# HDSC_HC32L110 register map
Vendor: HDSC Co.Ltd; Series: ARMCM0P; File version: 1.2
CPU: CM0 r0p0, little endian, no MPU, no FPU, 3 interrupt priority bits
Registers are 32-bit, read-write, reset 0x0 unless marked. A register's access mark holds for its fields unless they carry their own. Offsets are from the block's base; [hi:lo] are bit positions.

## BGR
Base 0x40002400; alternate view of ADC
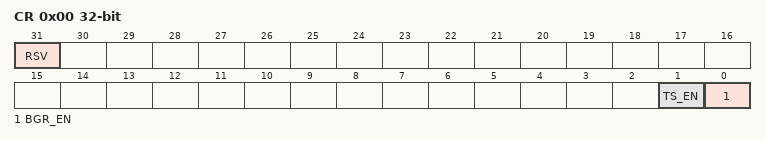
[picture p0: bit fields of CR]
0x00 CR (reset mask 0x3)
  [31] RSV, [1] TS_EN, [0] BGR_EN

## BT0 — desc BT
Base 0x40000C00
Same registers: BT1 0x40000C20, BT2 0x40000C40
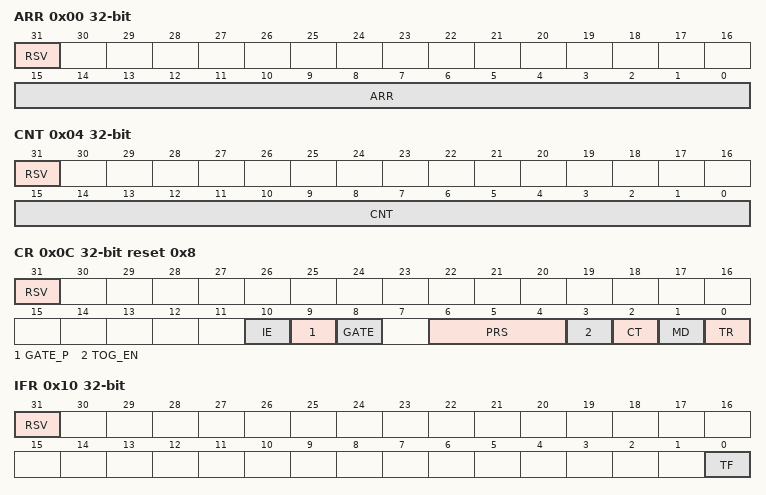
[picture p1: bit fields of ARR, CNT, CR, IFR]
0x00 ARR (reset mask 0xFF)
  [31] RSV, [15:0] ARR
0x04 CNT (reset mask 0xFF)
  [31] RSV, [15:0] CNT
0x08 CNT32
0x0C CR reset 0x8 (reset mask 0x77F)
  [31] RSV, [10] IE, [9] GATE_P, [8] GATE, [6:4] PRS, [3] TOG_EN, [2] CT, [1] MD, [0] TR
0x10 IFR ro (reset mask 0x1)
  [31] RSV rw, [0] TF
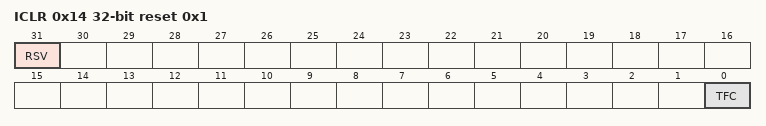
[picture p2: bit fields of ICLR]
0x14 ICLR wo reset 0x1 (reset mask 0x1)
  [31] RSV rw, [0] TFC

## CLK_TRIM
Base 0x40001800
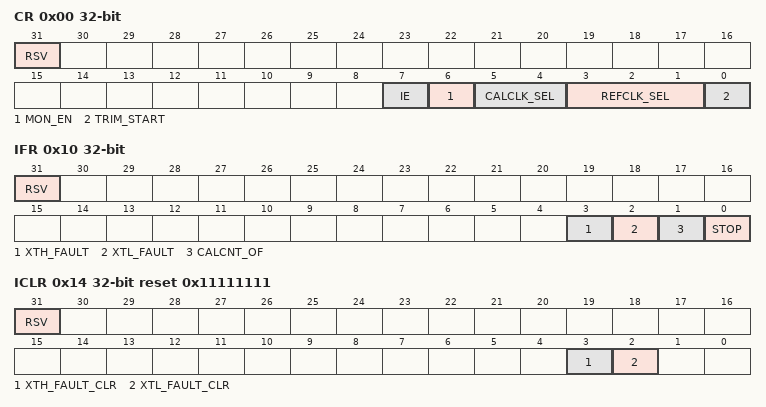
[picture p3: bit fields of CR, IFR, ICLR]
0x00 CR (reset mask 0xFF)
  [31] RSV, [7] IE, [6] MON_EN, [5:4] CALCLK_SEL, [3:1] REFCLK_SEL, [0] TRIM_START
0x04 REFCON
  [31:0] RCNTVAL
0x08 REFCNT ro
0x0C CALCNT ro
0x10 IFR ro (reset mask 0xF)
  [31] RSV rw, [3] XTH_FAULT, [2] XTL_FAULT, [1] CALCNT_OF, [0] STOP
0x14 ICLR reset 0x11111111 (reset mask 0xC)
  [31] RSV, [3] XTH_FAULT_CLR, [2] XTL_FAULT_CLR
0x18 CALCON reset 0xFFFFFFFF
  [31:0] CCNTVAL

## CLOCK
Base 0x40002000
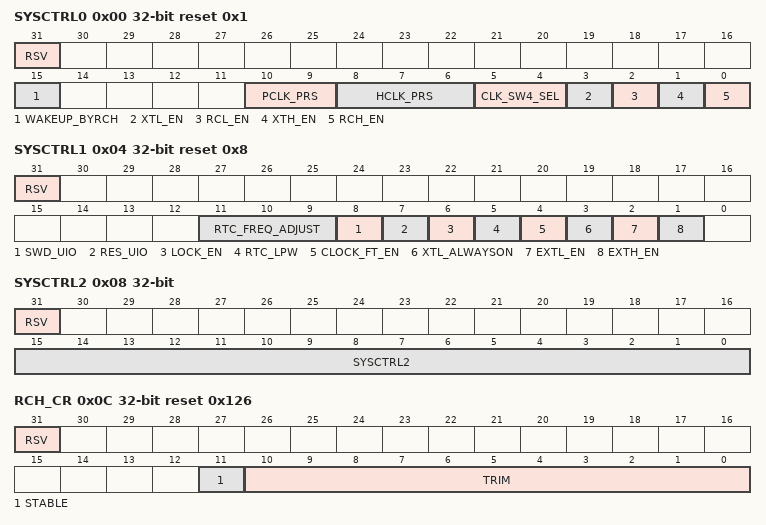
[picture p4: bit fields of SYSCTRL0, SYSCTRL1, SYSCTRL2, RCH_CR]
0x00 SYSCTRL0 reset 0x1 (reset mask 0x87FF)
  [31] RSV, [15] WAKEUP_BYRCH, [10:9] PCLK_PRS, [8:6] HCLK_PRS, [5:4] CLK_SW4_SEL, [3] XTL_EN, [2] RCL_EN, [1] XTH_EN, [0] RCH_EN
0x04 SYSCTRL1 reset 0x8 (reset mask 0xFFE)
  [31] RSV, [11:9] RTC_FREQ_ADJUST, [8] SWD_UIO, [7] RES_UIO, [6] LOCK_EN, [5] RTC_LPW, [4] CLOCK_FT_EN, [3] XTL_ALWAYSON, [2] EXTL_EN, [1] EXTH_EN
0x08 SYSCTRL2 (reset mask 0xFFFF)
  [31] RSV, [15:0] SYSCTRL2
0x0C RCH_CR reset 0x126 (reset mask 0xFFF)
  [31] RSV, [11] STABLE ro, [10:0] TRIM
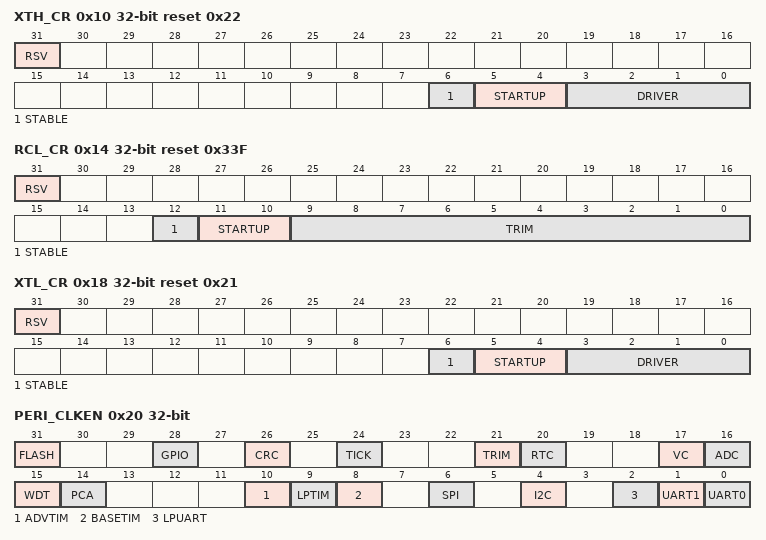
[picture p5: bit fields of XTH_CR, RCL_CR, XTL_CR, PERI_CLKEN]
0x10 XTH_CR reset 0x22 (reset mask 0x7F)
  [31] RSV, [6] STABLE ro, [5:4] STARTUP, [3:0] DRIVER
0x14 RCL_CR reset 0x33F (reset mask 0x1FFF)
  [31] RSV, [12] STABLE ro, [11:10] STARTUP, [9:0] TRIM
0x18 XTL_CR reset 0x21 (reset mask 0x7F)
  [31] RSV, [6] STABLE ro, [5:4] STARTUP, [3:0] DRIVER
0x20 PERI_CLKEN
  [31] FLASH, [28] GPIO, [26] CRC, [24] TICK, [21] TRIM, [20] RTC, [17] VC, [16] ADC, [15] WDT, [14] PCA, [10] ADVTIM, [9] LPTIM, [8] BASETIM, [6] SPI, [4] I2C, [2] LPUART, [1] UART1, [0] UART0
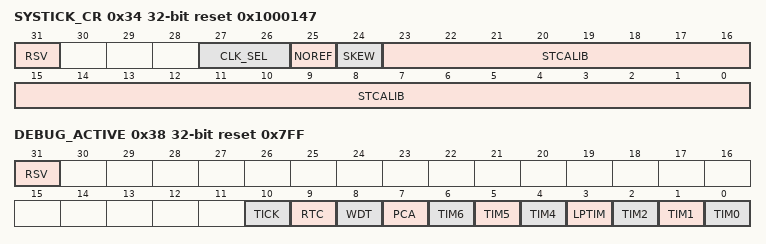
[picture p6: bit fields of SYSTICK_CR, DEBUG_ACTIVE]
0x34 SYSTICK_CR reset 0x1000147 (reset mask 0xFFFFFFF)
  [31] RSV, [27:26] CLK_SEL, [25] NOREF, [24] SKEW, [23:0] STCALIB
0x38 DEBUG_ACTIVE reset 0x7FF (reset mask 0x7FF)
  [31] RSV, [10] TICK, [9] RTC, [8] WDT, [7] PCA, [6] TIM6, [5] TIM5, [4] TIM4, [3] LPTIM, [2] TIM2, [1] TIM1, [0] TIM0

## CRC
Base 0x40020900
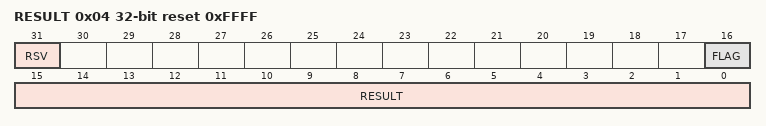
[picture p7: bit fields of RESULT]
0x04 RESULT reset 0xFFFF (reset mask 0x1FFFF)
  [31] RSV, [16] FLAG ro, [15:0] RESULT
0x80 DATA wo

## FLASH
Base 0x40020000
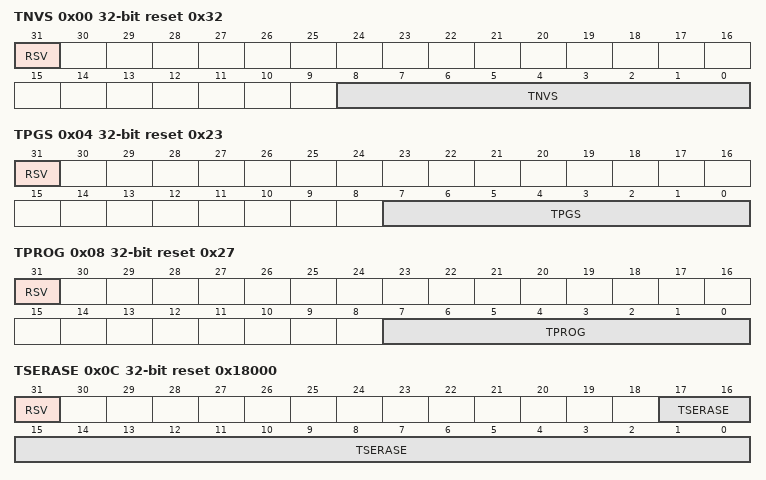
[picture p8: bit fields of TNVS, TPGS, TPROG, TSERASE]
0x00 TNVS reset 0x32 (reset mask 0x1FF)
  [31] RSV, [8:0] TNVS
0x04 TPGS reset 0x23 (reset mask 0xFF)
  [31] RSV, [7:0] TPGS
0x08 TPROG reset 0x27 (reset mask 0xFF)
  [31] RSV, [7:0] TPROG
0x0C TSERASE reset 0x18000 (reset mask 0x3FFFF)
  [31] RSV, [17:0] TSERASE
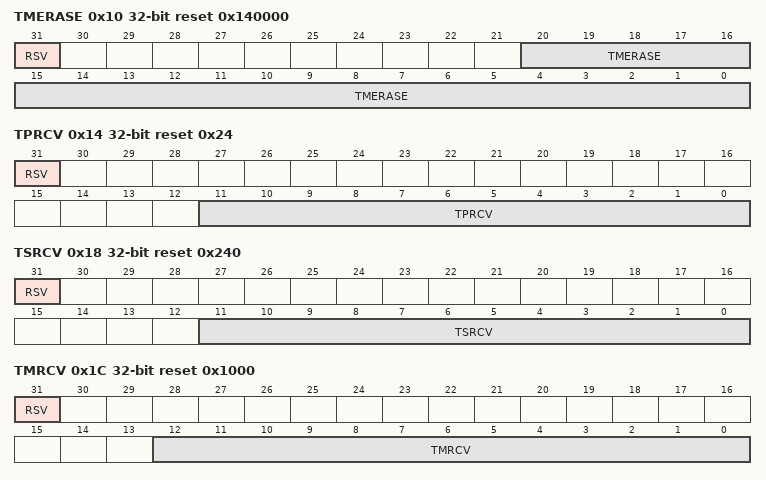
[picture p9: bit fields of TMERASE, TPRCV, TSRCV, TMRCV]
0x10 TMERASE reset 0x140000 (reset mask 0x1FFFFF)
  [31] RSV, [20:0] TMERASE
0x14 TPRCV reset 0x24 (reset mask 0xFFF)
  [31] RSV, [11:0] TPRCV
0x18 TSRCV reset 0x240 (reset mask 0xFFF)
  [31] RSV, [11:0] TSRCV
0x1C TMRCV reset 0x1000 (reset mask 0x1FFF)
  [31] RSV, [12:0] TMRCV
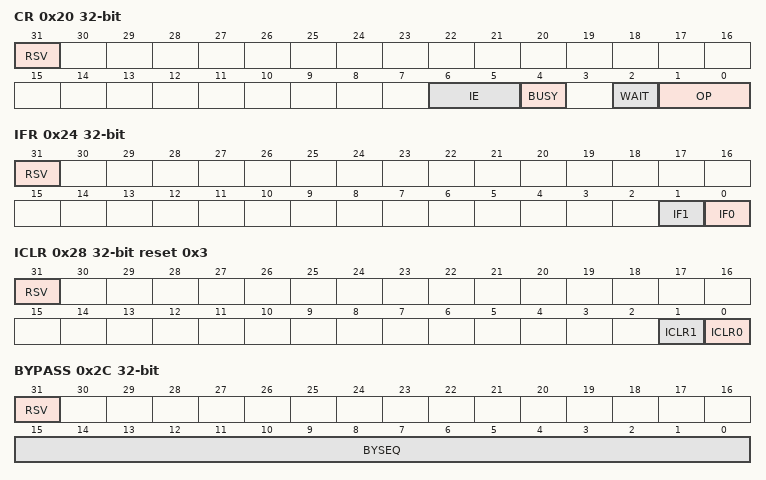
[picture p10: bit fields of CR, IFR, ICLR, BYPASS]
0x20 CR (reset mask 0x7F)
  [31] RSV, [6:5] IE, [4] BUSY ro, [2] WAIT, [1:0] OP
0x24 IFR ro (reset mask 0x3)
  [31] RSV rw, [1] IF1, [0] IF0
0x28 ICLR wo reset 0x3 (reset mask 0x3)
  [31] RSV rw, [1] ICLR1, [0] ICLR0
0x2C BYPASS wo (reset mask 0xFFFF)
  [31] RSV rw, [15:0] BYSEQ
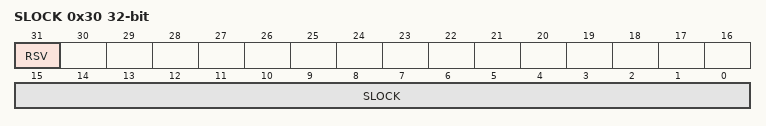
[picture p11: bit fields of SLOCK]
0x30 SLOCK (reset mask 0xFFFF)
  [31] RSV, [15:0] SLOCK

## I2C
Base 0x40000400
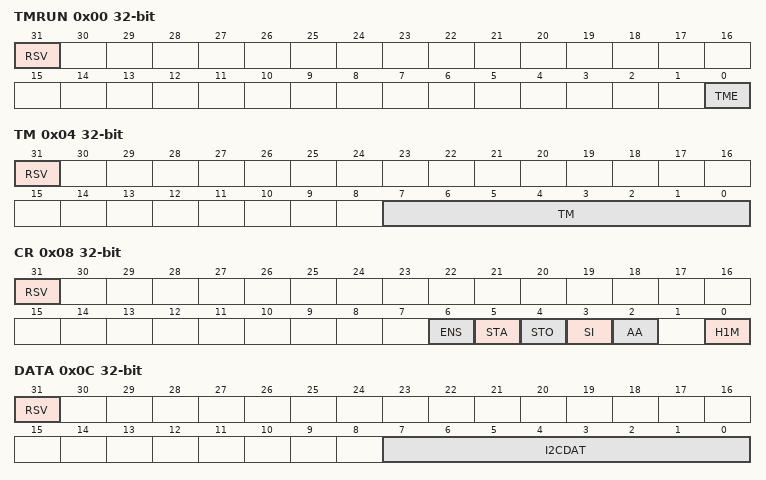
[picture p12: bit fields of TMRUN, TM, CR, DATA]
0x00 TMRUN (reset mask 0x1)
  [31] RSV, [0] TME
0x04 TM (reset mask 0xFF)
  [31] RSV, [7:0] TM
0x08 CR (reset mask 0x7D)
  [31] RSV, [6] ENS, [5] STA, [4] STO, [3] SI, [2] AA, [0] H1M
0x0C DATA (reset mask 0xFF)
  [31] RSV, [7:0] I2CDAT
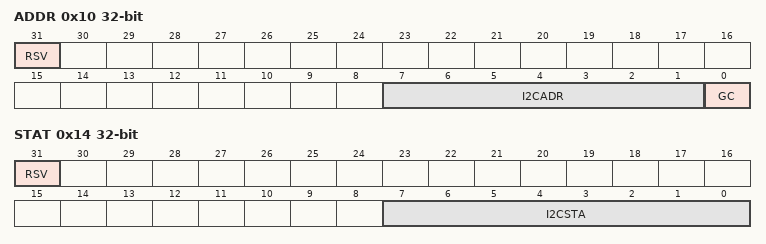
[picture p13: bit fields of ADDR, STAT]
0x10 ADDR (reset mask 0xFF)
  [31] RSV, [7:1] I2CADR, [0] GC
0x14 STAT ro (reset mask 0xFF)
  [31] RSV rw, [7:0] I2CSTA
